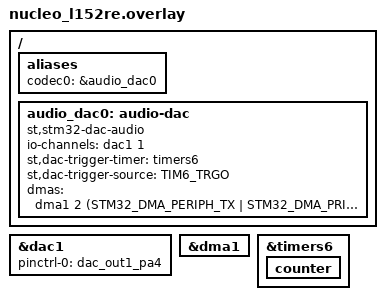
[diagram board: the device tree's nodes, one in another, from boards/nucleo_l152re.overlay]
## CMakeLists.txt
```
# SPDX-License-Identifier: Apache-2.0

cmake_minimum_required(VERSION 3.28.0)

find_package(Zephyr REQUIRED HINTS $ENV{ZEPHYR_BASE})
project(codec)

target_sources(app PRIVATE src/main.c)
```

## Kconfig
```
# SPDX-FileCopyrightText: Copyright The Zephyr Project Contributors
# SPDX-License-Identifier: Apache-2.0

source "Kconfig.zephyr"

config SAMPLE_TONE_HZ
	int "Playback tone frequency in Hz"
	range 20 7999
	default 440
	help
	  Frequency of the sine tone the sample plays. It must stay below
	  8000 Hz, half the 16 kHz sample rate. The default 440 Hz is the
	  reference pitch of the A4 note, so the tone can be checked against
	  a guitar tuner or a tuning fork.
```

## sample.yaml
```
sample:
  description: onchip audio codec example
    application
  name: audio codec sample
tests:
  sample.drivers.audio.codec:
    filter: dt_nodelabel_enabled("audcodec")
    tags: codec
    integration_platforms:
      - sf32lb52_devkit_lcd
    harness: console
    harness_config:
      type: multi_line
      ordered: true
      regex:
        - "Audio codec sample"
        - "Exiting"
```

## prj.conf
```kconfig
CONFIG_AUDIO=y
CONFIG_LOG=y
CONFIG_AUDIO_CODEC=y
CONFIG_HEAP_MEM_POOL_SIZE=32000
```

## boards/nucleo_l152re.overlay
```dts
/*
 * SPDX-FileCopyrightText: Copyright (c) 2026 Draeger
 * SPDX-License-Identifier: Apache-2.0
 */

/ {
	aliases {
		codec0 = &audio_dac0;
	};

	audio_dac0: audio-dac {
		compatible = "st,stm32-dac-audio";
		io-channels = <&dac1 1>;
		st,dac-trigger-timer = <&timers6>;
		st,dac-trigger-source = "TIM6_TRGO";
		dmas = <&dma1 2 (STM32_DMA_PERIPH_TX | STM32_DMA_PRIORITY_HIGH)>;
	};
};

&dac1 {
	status = "okay";
	pinctrl-0 = <&dac_out1_pa4>;
	pinctrl-names = "default";
};

&dma1 {
	status = "okay";
};

&timers6 {
	status = "okay";

	counter {
		status = "okay";
	};
};
```

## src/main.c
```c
/*
 * Copyright 2025 SiFli Technologies(Nanjing) Co., Ltd
 *
 * SPDX-License-Identifier: Apache-2.0
 */

#include <stdio.h>
#include <zephyr/device.h>
#include <zephyr/kernel.h>
#include <zephyr/devicetree.h>
#include <zephyr/audio/codec.h>
#include <zephyr/logging/log.h>
#include "sine.h"
LOG_MODULE_REGISTER(codec_sample);

#define TONE_SAMPLE_RATE 16000
#define AUDIO_BLOCK_SIZE 320
#define BLOCK_SAMPLES    (AUDIO_BLOCK_SIZE / sizeof(int16_t))
#define SPEAKER_VOL      15

static bool loopback;
static struct sine_gen tone_gen;

/* The tone is generated one block at a time. Alternate between two blocks so
 * the one handed to the codec is not overwritten by the next fill.
 */
static int16_t __aligned(4) tone_blocks[2][BLOCK_SAMPLES];
static uint8_t tone_block_idx;

static void tx_done(const struct device *dev, void *user_data)
{
	if (!loopback) {
		int16_t *block = tone_blocks[tone_block_idx];

		sine_gen_fill_s16(&tone_gen, block, BLOCK_SAMPLES, 1);
		audio_codec_write(dev, (uint8_t *)block, AUDIO_BLOCK_SIZE);
		tone_block_idx ^= 1U;
	}
}
static void rx_done(const struct device *dev, uint8_t *buf, uint32_t len, void *user_data)
{
	if (loopback) {
		audio_codec_write(dev, buf, AUDIO_BLOCK_SIZE);
	}
}

int main(void)
{
	static const struct device *dev;
	audio_property_value_t val;
	struct audio_codec_cfg cfg = {
		.dai_type = AUDIO_DAI_TYPE_PCM,
		.dai_cfg.pcm.dir = AUDIO_DAI_DIR_TX,
		.dai_cfg.pcm.pcm_width = AUDIO_PCM_WIDTH_16_BITS,
		.dai_cfg.pcm.channels = 1,
		.dai_cfg.pcm.block_size = AUDIO_BLOCK_SIZE,
		.dai_cfg.pcm.samplerate = AUDIO_PCM_RATE_16K,
	};

	LOG_INF("Audio codec sample");
	sine_gen_init(&tone_gen, CONFIG_SAMPLE_TONE_HZ, TONE_SAMPLE_RATE);
#if DT_NODE_HAS_STATUS_OKAY(DT_ALIAS(codec0))
	dev = DEVICE_DT_GET(DT_ALIAS(codec0));
#else
	LOG_ERR("No audio codec on this board. Skipping audio test.\n");
	return 0;
#endif
	if (!device_is_ready(dev)) {
		LOG_ERR("codec device is not ready\n");
		return -EBUSY;
	}
	LOG_INF("codec device is ready");
	k_sleep(K_MSEC(1000));

	LOG_INF("codec playback example");
	loopback = false;
	if (audio_codec_configure(dev, &cfg) < 0) {
		LOG_ERR("configure codec error\n");
		return -EIO;
	}
	if (audio_codec_register_done_callback(dev, tx_done, NULL, rx_done, NULL) < 0) {
		LOG_ERR("could not register codec callbacks\n");
		return -EIO;
	}
	audio_codec_start(dev, AUDIO_DAI_DIR_TX);
	LOG_INF("playback started");
	val.vol = SPEAKER_VOL;
	if (audio_codec_set_property(dev, AUDIO_PROPERTY_OUTPUT_VOLUME, 0, val) < 0) {
		LOG_ERR("could not set volume\n");
		return -EIO;
	}
	k_sleep(K_MSEC(15000));
	audio_codec_stop(dev, AUDIO_DAI_DIR_TX);
	LOG_INF("codec transfer stopped");

	LOG_INF("codec loopback example");
	loopback = true;
	cfg.dai_cfg.pcm.dir = AUDIO_DAI_DIR_TXRX;
	if (audio_codec_configure(dev, &cfg) < 0) {
		LOG_ERR("configure codec error\n");
		return -EIO;
	}
	if (audio_codec_register_done_callback(dev, tx_done, NULL, rx_done, NULL) < 0) {
		LOG_ERR("could not register codec callbacks\n");
		return -EIO;
	}
	audio_codec_start(dev, AUDIO_DAI_DIR_TXRX);
	LOG_INF("loopback started");
	if (audio_codec_set_property(dev, AUDIO_PROPERTY_OUTPUT_VOLUME, 0, val) < 0) {
		LOG_ERR("could not set volume\n");
		return -EIO;
	}
	k_sleep(K_MSEC(15000));
	audio_codec_stop(dev, AUDIO_DAI_DIR_TXRX);
	LOG_INF("loopback stopped");

	LOG_INF("Exiting");
	return 0;
}
```

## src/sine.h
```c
/*
 * SPDX-FileCopyrightText: Copyright The Zephyr Project Contributors
 * SPDX-License-Identifier: Apache-2.0
 */

#ifndef ZEPHYR_SAMPLES_DRIVERS_AUDIO_CODEC_SINE_H_
#define ZEPHYR_SAMPLES_DRIVERS_AUDIO_CODEC_SINE_H_

#include <stddef.h>
#include <stdint.h>

/*
 * Integer-only sine tone generator.
 *
 * A 256-entry signed 16-bit quarter-symmetric lookup table is walked with a
 * 16.16 fixed-point phase accumulator and linear interpolation between the two
 * nearest entries, so any frequency can be produced at any sample rate without
 * floating point and without a baked PCM table.
 */

#define SINE_POINTS    256
#define SINE_MASK      (SINE_POINTS - 1)
#define SINE_FRAC_BITS 16U

/* One sine period, peak 16384 (about -6 dBFS). */
static const int16_t sine_table[SINE_POINTS] = {
	     0,    402,    804,   1205,   1606,   2006,   2404,   2801,
	  3196,   3590,   3981,   4370,   4756,   5139,   5520,   5897,
	  6270,   6639,   7005,   7366,   7723,   8076,   8423,   8765,
	  9102,   9434,   9760,  10080,  10394,  10702,  11003,  11297,
	 11585,  11866,  12140,  12406,  12665,  12916,  13160,  13395,
	 13623,  13842,  14053,  14256,  14449,  14635,  14811,  14978,
	 15137,  15286,  15426,  15557,  15679,  15791,  15893,  15986,
	 16069,  16143,  16207,  16261,  16305,  16340,  16364,  16379,
	 16384,  16379,  16364,  16340,  16305,  16261,  16207,  16143,
	 16069,  15986,  15893,  15791,  15679,  15557,  15426,  15286,
	 15137,  14978,  14811,  14635,  14449,  14256,  14053,  13842,
	 13623,  13395,  13160,  12916,  12665,  12406,  12140,  11866,
	 11585,  11297,  11003,  10702,  10394,  10080,   9760,   9434,
	  9102,   8765,   8423,   8076,   7723,   7366,   7005,   6639,
	  6270,   5897,   5520,   5139,   4756,   4370,   3981,   3590,
	  3196,   2801,   2404,   2006,   1606,   1205,    804,    402,
	     0,   -402,   -804,  -1205,  -1606,  -2006,  -2404,  -2801,
	 -3196,  -3590,  -3981,  -4370,  -4756,  -5139,  -5520,  -5897,
	 -6270,  -6639,  -7005,  -7366,  -7723,  -8076,  -8423,  -8765,
	 -9102,  -9434,  -9760, -10080, -10394, -10702, -11003, -11297,
	-11585, -11866, -12140, -12406, -12665, -12916, -13160, -13395,
	-13623, -13842, -14053, -14256, -14449, -14635, -14811, -14978,
	-15137, -15286, -15426, -15557, -15679, -15791, -15893, -15986,
	-16069, -16143, -16207, -16261, -16305, -16340, -16364, -16379,
	-16384, -16379, -16364, -16340, -16305, -16261, -16207, -16143,
	-16069, -15986, -15893, -15791, -15679, -15557, -15426, -15286,
	-15137, -14978, -14811, -14635, -14449, -14256, -14053, -13842,
	-13623, -13395, -13160, -12916, -12665, -12406, -12140, -11866,
	-11585, -11297, -11003, -10702, -10394, -10080,  -9760,  -9434,
	 -9102,  -8765,  -8423,  -8076,  -7723,  -7366,  -7005,  -6639,
	 -6270,  -5897,  -5520,  -5139,  -4756,  -4370,  -3981,  -3590,
	 -3196,  -2801,  -2404,  -2006,  -1606,  -1205,   -804,   -402,
};

struct sine_gen {
	uint32_t phase;     /* 16.16 fixed-point index into sine_table */
	uint32_t phase_inc; /* phase step per output frame */
};

/*
 * Set up gen to produce freq_hz at sample_rate_hz. sample_rate_hz must be
 * non-zero and larger than twice freq_hz to stay below Nyquist.
 */
static inline void sine_gen_init(struct sine_gen *gen, uint32_t freq_hz, uint32_t sample_rate_hz)
{
	gen->phase = 0U;
	gen->phase_inc =
		(uint32_t)(((uint64_t)freq_hz << SINE_FRAC_BITS) * SINE_POINTS / sample_rate_hz);
}

/* Return the next 16-bit sample and advance the phase. */
static inline int16_t sine_gen_next(struct sine_gen *gen)
{
	uint32_t idx = (gen->phase >> SINE_FRAC_BITS) & SINE_MASK;
	int32_t frac = (int32_t)(gen->phase & ((1U << SINE_FRAC_BITS) - 1U));
	int32_t s0 = sine_table[idx];
	int32_t s1 = sine_table[(idx + 1U) & SINE_MASK];

	gen->phase += gen->phase_inc;

	return (int16_t)(s0 + (((s1 - s0) * frac) >> SINE_FRAC_BITS));
}

/*
 * Fill dst with frames interleaved 16-bit samples, the same value written to
 * each of channels lanes per frame. dst holds frames * channels int16_t.
 */
static inline void sine_gen_fill_s16(struct sine_gen *gen, int16_t *dst, size_t frames,
				     uint8_t channels)
{
	size_t f;
	uint8_t c;

	for (f = 0; f < frames; f++) {
		int16_t sample = sine_gen_next(gen);

		for (c = 0; c < channels; c++) {
			*dst++ = sample;
		}
	}
}

#endif /* ZEPHYR_SAMPLES_DRIVERS_AUDIO_CODEC_SINE_H_ */
```
